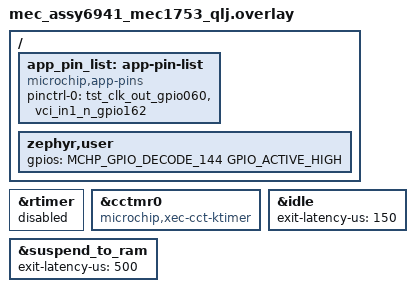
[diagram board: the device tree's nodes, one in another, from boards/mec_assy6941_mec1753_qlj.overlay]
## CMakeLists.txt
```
# Copyright (c) 2026 Microchip Technology Inc.
#
# SPDX-License-Identifier: Apache-2.0

cmake_minimum_required(VERSION 3.20.0)

find_package(Zephyr REQUIRED HINTS $ENV{ZEPHYR_BASE})
project(xec_cct_kt)

target_sources(app PRIVATE src/main.c src/xec_vci.c)
```

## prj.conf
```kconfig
# Copyright (c) 2026 Microchip Technology Inc.
# SPDX-License-Identifier: Apache-2.0

# Tickless kernel and PM are prerequisites for the system-timer LPM companion;
# MCHP_XEC_CCT_KTIMER then selects SYSTEM_TIMER_LPM_COMPANION_HOOKS.
CONFIG_TICKLESS_KERNEL=y
CONFIG_PM=y

CONFIG_STDOUT_CONSOLE=y

# main.c applies the test-clock-out pin state via the pinctrl API.
CONFIG_PINCTRL=y

CONFIG_SOC_MEC_PM_DBG_PCR_CLK_REQ_VBM=y
```

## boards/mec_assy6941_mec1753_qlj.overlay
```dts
/*
 * Copyright (c) 2026 Microchip Technology Inc.
 *
 * SPDX-License-Identifier: Apache-2.0
 *
 * Make the MEC1753-QLJ board use the capture-compare timer (CCT) as the Zephyr
 * kernel timer instead of the default RTOS timer.
 *
 * - cctmr0 is bound to the CCT kernel-timer driver and given the values its
 *   binding/driver require (compatible, the Compare0/Compare1 interrupts and
 *   GIRQ encodings, PCR sleep-enable, and input clock).
 * - The RTOS timer remains as the low-power companion. In HOOKS mode no driver
 *   binds it; the CCT driver reaches it by the &rtimer node label, so the node
 *   stays present but disabled (which also keeps MCHP_XEC_RTOS_TIMER from being
 *   auto-selected and conflicting with the CCT kernel timer).
 */

#include <zephyr/dt-bindings/gpio/microchip-xec-gpio.h>
#include <zephyr/dt-bindings/interrupt-controller/mchp-xec-ecia.h>
#include <zephyr/dt-bindings/clock/mchp_xec_pcr.h>

/ {
	/*
	 * Route the MEC internal test clock to GPIO060 (alternate function 2) so
	 * the timer clock can be observed on a scope. This pin is not owned by any
	 * device driver, so main.c applies this state via the pinctrl API. NOTE:
	 * the pin mux only connects the pad; which clock is driven out is selected
	 * separately in SoC clock-out/VBAT test logic and is not configured here.
	 */
	app_pin_list: app-pin-list {
		/* App-local binding (dts/bindings/microchip,xec-test-clk-out.yaml)
		 * includes pinctrl-device.yaml so pinctrl-0/pinctrl-names are typed
		 * properties -- required for PINCTRL_DT_DEFINE() in main.c to compile.
		 */
		compatible = "microchip,app-pins";
		pinctrl-0 = <&tst_clk_out_gpio060 &vci_in1_n_gpio162>;
		pinctrl-names = "default";
	};

	zephyr,user {
		gpios = <MCHP_GPIO_DECODE_144 GPIO_ACTIVE_HIGH>;
	};
};

&rtimer {
	status = "disabled";
};

&cctmr0 {
	compatible = "microchip,xec-cct-ktimer";
	status = "okay";
};

/*
 * The PM core arms the LPM companion (z_sys_clock_lpm_enter) only when the
 * chosen power state has a non-zero exit-latency-us: the single
 * sys_clock_set_timeout(..., idle=true) call at subsys/pm/pm.c is gated on
 * exit_latency_ticks > 0. Without it, SUSPEND_TO_RAM powers the PLL (and the
 * CCT) off with no companion armed and therefore no wake source, so the core
 * hangs in __WFI(). The board's power-states omit exit-latency-us, so add it
 * here. Values must be >= one tick (100 us at 10 kHz) to survive the floor
 * conversion; these are placeholders pending measured PLL-relock/restore time.
 */
&idle {
	exit-latency-us = <150>;
};

&suspend_to_ram {
	exit-latency-us = <500>;
};
```

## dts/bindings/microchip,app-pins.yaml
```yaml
# Copyright (c) 2026 Microchip Technology Inc.
# SPDX-License-Identifier: Apache-2.0

description: |
  Sample-only pin-control holder for routing the MEC internal test clock to a
  GPIO pad (see samples/boards/microchip/xec_cct_kt). It has no registers and no
  driver; it exists solely so a pin-control state can be declared and applied
  from the application with the pinctrl API.

  Including pinctrl-device.yaml is what makes the pinctrl-0/pinctrl-names
  properties typed in the binding, which is required for PINCTRL_DT_DEFINE()
  (it expands to DT_FOREACH_PROP_ELEM(node, pinctrl_0, ...), whose helper macro
  is only generated for a binding-declared property).

compatible: "microchip,app-pins"

include: [base.yaml, pinctrl-device.yaml]
```

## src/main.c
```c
/*
 * Copyright (c) 2026 Microchip Technology Inc.
 *
 * SPDX-License-Identifier: Apache-2.0
 */

#include <soc.h>
#include <zephyr/kernel.h>
#include <zephyr/sys/printk.h>
#include <zephyr/drivers/gpio.h>
#include <zephyr/drivers/pinctrl.h>

#include "xec_vci.h"

/* #define USE_VCI_IN1_BUTTON */

#define SLEEP_MS   3000U
#define ITERATIONS 0

#define XEC_VBAT_MEM_BASE  DT_REG_ADDR(DT_NODELABEL(bbram))
#define XEC_ECS_BASE       DT_REG_ADDR(DT_NODELABEL(ecs))
#define XEC_ECS_DBG_CR_OFS 0x20U

/* Test-clock-out pad (GPIO060, AF2). Not owned by a device driver, so define
 * its pin-control config here and apply it manually from main().
 */
#define APP_PINS_NODE DT_NODELABEL(app_pin_list)
PINCTRL_DT_DEFINE(APP_PINS_NODE);
static const struct pinctrl_dev_config *app_pins_pcfg = PINCTRL_DT_DEV_CONFIG_GET(APP_PINS_NODE);

#ifndef USE_VCI_IN1_BUTTON
#define ZEPHYR_USER_NODE DT_PATH(zephyr_user)
static const struct gpio_dt_spec sw2_spec = GPIO_DT_SPEC_GET(ZEPHYR_USER_NODE, gpios);
static volatile uint32_t sw2_falling_edge;
static struct gpio_callback sw2_cbs;
static void sw2_cb(const struct device *port, struct gpio_callback *cb, gpio_port_pins_t pins);
#endif

/*
 * Exercise the CCT kernel timer across tickless sleeps. Each iteration sleeps
 * long enough to let the PM policy enter a low-power state (the board's
 * suspend-to-ram residency is 2 s), which hands timekeeping to the 32 KHz RTOS
 * timer companion. If both the system timer and the LPM hooks are correct, the
 * uptime delta and the free-running cycle-counter delta should both track the
 * requested sleep time.
 */
int main(void)
{
	uint32_t i = 0, r = 0;
	int ret = 0;

	printk("XEC CCT kernel timer sample\n");
	printk("system timer HW cycles/sec: %u\n", sys_clock_hw_cycles_per_sec());
	printk("ticks/sec: %d\n", CONFIG_SYS_CLOCK_TICKS_PER_SEC);

	/* Route the test clock to GPIO060 for scope measurement. */
	ret = pinctrl_apply_state(app_pins_pcfg, PINCTRL_STATE_DEFAULT);
	if (ret != 0) {
		printk("app-pin-list pinctrl apply failed: %d\n", ret);
	} else {
		printk("test clock routed to GPIO060 (AF2)\n");
		printk("VCI_IN1 pin function enabled\n");
	}

#ifdef USE_VCI_IN1_BUTTON
	printk("Using VCI_IN1 on switch S4 of EVB as trigger");
	mchp_vci_in_input_enable(BIT(MEC_VCI_IN1_POS));
	mchp_vci_in_latch_enable(BIT(MEC_VCI_IN1_POS));
	mchp_vci_edge_detect_clr_all();
	mchp_vci_in_latch_reset(BIT(MEC_VCI_IN1_POS));
#else
	printk("Using GPIO144 connected to switch SW2 of MECC as trigger\n");
	gpio_flags_t sw2_flags = GPIO_INPUT | GPIO_INT_EDGE_FALLING;
	gpio_port_pins_t pin_mask = BIT(sw2_spec.pin);

	ret = gpio_pin_configure_dt(&sw2_spec, sw2_flags);
	if (ret != 0) {
		printk("configuration of SW2 GPIO as input failed (%d)\n", ret);
		return ret;
	}

	gpio_init_callback(&sw2_cbs, sw2_cb, pin_mask);
	gpio_add_callback(sw2_spec.port, &sw2_cbs);

	ret = gpio_pin_interrupt_configure_dt(&sw2_spec, sw2_flags);
	if (ret != 0) {
		printk("configure SW2 GPIO falling edge interrupt failed (%d)\n", ret);
		return ret;
	}
#endif

#ifdef USE_VCI_IN1_BUTTON
	printk("Disconnect Debugger and press switch S4 when ready\n");
#else
	printk("Disconnect Debugger and press switch SW2 when ready\n");
#endif

#ifdef USE_VCI_IN1_BUTTON
	r = mchp_vci_pedge_detect() & mchp_vci_nedge_detect();
	while ((r & BIT(MEC_VCI_IN1_POS)) == 0) {
		r = mchp_vci_pedge_detect() & mchp_vci_nedge_detect();
	}
	printk("Button S4 pressed. Disabling Debug interface\n");
#else
	sw2_falling_edge = 0;
	while (sw2_falling_edge == 0) {
	}
	printk("Button SW2 pressed. Disabling Debug interface\n");
#endif

	sys_write32(0, XEC_ECS_BASE + XEC_ECS_DBG_CR_OFS);
	sys_write32(0, 0xE000EDFCU);
	sys_write32(0xA05F0000U, 0xE0000EDFU);
	sys_write32(0xC5ACCE55U, 0xE0000FB0U);
	sys_write32(0, 0xE0000FB0U);
	sys_write32(0, 0xE0000E80U);
	sys_write32(0, 0xE0040304U);
	sys_write32(0, 0xE000EDFCU);

	r = sys_read32(XEC_ECS_BASE + XEC_ECS_DBG_CR_OFS);
	printk("ECS reg 0x%08x = 0x%08x\n", (XEC_ECS_BASE + XEC_ECS_DBG_CR_OFS), r);

#if ITERATIONS == 0
	while (true) {
		i++;
#else
	for (i = 0; i < ITERATIONS; i++) {
#endif
		uint32_t cyc0 = k_cycle_get_32();
		int64_t up0 = k_uptime_get();

		k_msleep(SLEEP_MS);

		uint32_t cyc1 = k_cycle_get_32();
		int64_t up1 = k_uptime_get();

		/* Unsigned subtraction is wrap-correct for the 32-bit counter. */
		uint32_t dcyc = cyc1 - cyc0;

		printk("iter %u: requested %u ms, uptime +%lld ms, "
		       "cycles +%u (%u ms by cycle count)\n",
		       i, SLEEP_MS, (long long)(up1 - up0), dcyc, k_cyc_to_ms_near32(dcyc));

		r = sys_read32(XEC_VBAT_MEM_BASE);
		printk("PCR CLK_REQ0 = 0x%08x\n", r);
		r = sys_read32(XEC_VBAT_MEM_BASE + 4U);
		printk("PCR CLK_REQ1 = 0x%08x\n", r);
		r = sys_read32(XEC_VBAT_MEM_BASE + 8U);
		printk("PCR CLK_REQ2 = 0x%08x\n", r);
		r = sys_read32(XEC_VBAT_MEM_BASE + 0xCU);
		printk("PCR CLK_REQ3 = 0x%08x\n", r);
		r = sys_read32(XEC_VBAT_MEM_BASE + 0x10U);
		printk("PCR CLK_REQ4 = 0x%08x\n", r);

		k_busy_wait(1000U); /* Let UART TX FIFO drain */
	}

	printk("Sample complete\n");

	return 0;
}

#ifndef USE_VCI_IN1_BUTTON
static void sw2_cb(const struct device *port, struct gpio_callback *cb, gpio_port_pins_t pins)
{
	sw2_falling_edge = 1U;
}
#endif
```

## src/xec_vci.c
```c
/*
 * Copyright 2024 Microchip Technology Inc. and its subsidiaries.
 *
 * SPDX-License-Identifier: Apache-2.0
 */
#include <stddef.h>
#include <stdint.h>
#include <soc.h>
#include <zephyr/kernel.h>
#include <zephyr/sys/printk.h>
#include <zephyr/drivers/pinctrl.h>

#include "xec_vci.h"

#define XEC_VCI_NODE DT_NODELABEL(vci0)

#define XEC_VCI_REG_BASE (mm_reg_t)(DT_REG_ADDR(XEC_VCI_NODE))

#define XEC_VCI_CR_OFS            0
#define XEC_VCI_LATCH_EN_OFS      4U
#define XEC_VCI_LATCH_RST_OFS     8U
#define XEC_VCI_INPUT_EN_OFS      0xCU
#define XEC_VCI_HOLD_OFF_CNT_OFS  0x10U
#define XEC_VCI_IN_POLARITY_OFS   0x14U
#define XEC_VCI_IN_POSEDG_STS_OFS 0x18U
#define XEC_VCI_IN_NEGEDG_STS_OFS 0x1CU
#define XEC_VCI_IN_VBAT_BUFEN_OFS 0x20U

/* Control register */
#define XEC_VCI_CR_LIN_POS          0 /* R/O latched input states */
#define XEC_VCI_CR_LIN_MSK          GENMASK(6, 0)
#define XEC_VCI_CR_LIN_GET(r)       FIELD_GET(XEC_VCI_CR_LIN_MSK, (r))
#define XEC_VCI_CR_OVRD_IN_POS      8  /* R/O current VCI_OVRD_IN pin state*/
#define XEC_VCI_CR_OUTV_POS         9  /* R/O current VCI_OUT pin state */
#define XEC_VCI_CR_FW_OUTV_POS      10 /* R/W VCI_OUT pin state under FW control */
#define XEC_VCI_CR_FW_EN_POS        11 /* R/W enable FW control of VCI_OUT pin state */
#define XEC_VCI_CR_FILT_BYPASS_POS  12 /* R/W bypass(disable) input filters */
#define XEC_VCI_CR_WK_ALRM_STS_POS  16 /* R/O Week alarm asserted WEEK_ALRM_LS signal */
#define XEC_VCI_CR_RTC_ALRM_STS_POS 17 /* R/O RTC asserted its alarm signal */
#define XEC_VCI_CR_SEL_SYSPP_POS    18 /* R/W 1=VCI_IN3 becomes SYSPWR_PRES */

#define XEC_VCI_CR_ALL_IN_STATE_MSK                                                                \
	(XEC_VCI_CR_LIN_MSK | BIT(XEC_VCI_CR_OVRD_IN_POS) | BIT(XEC_VCI_CR_OUTV_POS) |             \
	 BIT(XEC_VCI_CR_WK_ALRM_STS_POS) | BIT(XEC_VCI_CR_RTC_ALRM_STS_POS))

/* Latch enable and Latch reset registers */
#define XEC_VCI_LER_IN_POS       0 /* Latch enable/reset for VCI_IN pins */
#define XEC_VCI_LER_IN_MSK       GENMASK(6, 0)
#define XEC_VCI_LER_SET(v)       FIELD_PREP(XEC_VCI_LER_IN_MSK, (v))
#define XEC_VCI_LER_GET(r)       FIELD_GET(XEC_VCI_LER_IN_MSK, (r))
#define XEC_VCI_LER_WK_ALRM_POS  16
#define XEC_VCI_LER_RTC_ALRM_POS 17

#define XEC_VCI_LER_ALL_MSK                                                                        \
	(XEC_VCI_LER_IN_MSK | BIT(XEC_VCI_LER_WK_ALRM_POS) | BIT(XEC_VCI_LER_RTC_ALRM_POS))

/* Input enable register */
#define XEC_VCI_INPUT_EN_VIN_POS    0
#define XEC_VCI_INPUT_EN_VIN_MSK    GENMASK(6, 0)
#define XEC_VCI_INPUT_EN_VIN_SET(v) FIELD_PREP(XEC_VCI_INPUT_EN_VIN_MSK, (v))
#define XEC_VCI_INPUT_EN_VIN_GET(r) FIELD_GET(XEC_VCI_INPUT_EN_VIN_MSK, (r))

/* Hold off count register. Units of 125 ms */
#define XEC_VCI_HOLD_OFF_CNT_TM_POS    0
#define XEC_VCI_HOLD_OFF_CNT_TM_MSK    GENMASK(7, 0)
#define XEC_VCI_HOLD_OFF_CNT_TM_SET(v) FIELD_PREP(XEC_VCI_HOLD_OFF_CNT_TM_MSK, (v))
#define XEC_VCI_HOLD_OFF_CNT_TM_GET(r) FIELD_GET(XEC_VCI_HOLD_OFF_CNT_TM_MSK, (r))

/* Input Polarity register */
#define XEC_VCI_IN_POLARITY_POS    0
#define XEC_VCI_IN_POLARITY_MSK    GENMASK(6, 0)
#define XEC_VCI_IN_POLARITY_SET(v) FIELD_PREP(XEC_VCI_IN_POLARITY_MSK, (v))
#define XEC_VCI_IN_POLARITY_GET(r) FIELD_GET(XEC_VCI_IN_POLARITY_MSK, (r))

/* Positive and Negative Edge detect registers */
#define XEC_VCI_EDG_DET_POS    0
#define XEC_VCI_EDG_DET_MSK    GENMASK(6, 0)
#define XEC_VCI_EDG_DET_SET(v) FIELD_PREP(XEC_VCI_EDG_DET_MSK, (v))
#define XEC_VCI_EDG_DET_GET(r) FIELD_GET(XEC_VCI_EDG_DET_MSK, (r))

/* Input VBAT buffer enable register */
#define XEC_VCI_IN_VB_EN_POS    0
#define XEC_VCI_IN_VB_EN_MSK    GENMASK(6, 0)
#define XEC_VCI_IN_VB_EN_SET(v) FIELD_PREP(XEC_VCI_IN_VB_EN_MSK, (v))
#define XEC_VCI_IN_VB_EN_GET(r) FIELD_GET(XEC_VCI_IN_VB_EN_MSK, (r))

/* VCI_IN[0:6] are always bits[0:5] in registers referencing them */
#define XEC_VCI_IN_0_6_MASK 0x3fu

/* -------- VBAT Powered Control Interface (VCI) API -------- */

int mchp_xec_vci_pin_disable(uint8_t vci_id)
{
	mm_reg_t base = XEC_VCI_REG_BASE;

	if (vci_id >= MCHP_XEC_VCI_IN_ID_MAX) {
		return -EINVAL;
	}

	sys_clear_bit(base + XEC_VCI_INPUT_EN_OFS, vci_id);
	sys_clear_bit(base + XEC_VCI_IN_VBAT_BUFEN_OFS, vci_id);

	return 0;
}

/* VCI_IN pins filter enable/disable */
void mchp_vci_in_filter_enable(uint8_t enable)
{
	mm_reg_t base = XEC_VCI_REG_BASE;

	if (enable != 0) {
		sys_clear_bit(base + XEC_VCI_CR_OFS, XEC_VCI_CR_FILT_BYPASS_POS);
	} else {
		sys_set_bit(base + XEC_VCI_CR_OFS, XEC_VCI_CR_FILT_BYPASS_POS);
	}
}

/* Return current state of VCI pin inputs. If latching is enabled
 * the current state is the latched state otherwise the state is
 * live pin after filtering and polarity are applied.
 * b[6:0] = VCI_IN[6:0]
 * b[8] = current VCI_OVRD_IN state
 * b[9] = current VCI_OUT state
 * b[16] = Week Alarm state
 * b[17] = RTC Alaram state
 */
uint32_t mchp_vci_in_pin_states(void)
{
	mm_reg_t base = XEC_VCI_REG_BASE;

	return sys_read32(base + XEC_VCI_CR_OFS) & XEC_VCI_CR_ALL_IN_STATE_MSK;
}

uint8_t mchp_vci_out_get(void)
{
	mm_reg_t base = XEC_VCI_REG_BASE;

	if ((sys_test_bit(base + XEC_VCI_CR_OFS, XEC_VCI_CR_OUTV_POS)) != 0) {
		return 1U;
	}

	return 0;
}

uint8_t mchp_vci_ovrd_in_get(void)
{
	mm_reg_t base = XEC_VCI_REG_BASE;

	if ((sys_test_bit(base + XEC_VCI_CR_OFS, XEC_VCI_CR_OVRD_IN_POS)) != 0) {
		return 1U;
	}

	return 0;
}

/* Enable software control of VCI_OUT pin state */
void mchp_vci_sw_vci_out_enable(uint8_t enable)
{
	mm_reg_t base = XEC_VCI_REG_BASE;

	if (enable != 0) {
		sys_set_bit(base + XEC_VCI_CR_OFS, XEC_VCI_CR_FW_EN_POS);
	} else {
		sys_clear_bit(base + XEC_VCI_CR_OFS, XEC_VCI_CR_FW_EN_POS);
	}
}

/* set the state of software controlled VCI_OUT pin state
 * This value has no effect on VCI_OUT pin unless the FW_EXT bit is 1.
 */
void mchp_vci_sw_vci_out_set(uint8_t pin_state)
{
	mm_reg_t base = XEC_VCI_REG_BASE;

	if (pin_state != 0) {
		sys_set_bit(base + XEC_VCI_CR_OFS, XEC_VCI_CR_FW_OUTV_POS);
	} else {
		sys_clear_bit(base + XEC_VCI_CR_OFS, XEC_VCI_CR_FW_OUTV_POS);
	}
}

uint32_t mchp_vci_in_latched_get(void)
{
	mm_reg_t base = XEC_VCI_REG_BASE;
	uint32_t r = sys_read32(base + XEC_VCI_CR_OFS);

	return XEC_VCI_CR_LIN_GET(r);
}

void mchp_vci_in_latch_enable(uint32_t latch_bitmap)
{
	mm_reg_t base = XEC_VCI_REG_BASE;
	uint32_t v = XEC_VCI_LER_SET(latch_bitmap);

	sys_set_bits(base + XEC_VCI_LATCH_EN_OFS, v);
}

void mchp_vci_in_latch_disable(uint32_t latch_bitmap)
{
	mm_reg_t base = XEC_VCI_REG_BASE;
	uint32_t v = XEC_VCI_LER_SET(latch_bitmap);

	sys_clear_bits(base + XEC_VCI_LATCH_EN_OFS, v);
}

uint32_t mchp_vci_in_latch_enable_get(void)
{
	mm_reg_t base = XEC_VCI_REG_BASE;
	uint32_t r = sys_read32(base + XEC_VCI_LATCH_EN_OFS);

	return XEC_VCI_LER_GET(r);
}

void mchp_vci_in_latch_reset(uint32_t latch_bitmap)
{
	mm_reg_t base = XEC_VCI_REG_BASE;

	sys_write32(latch_bitmap & XEC_VCI_LER_ALL_MSK, base + XEC_VCI_LATCH_RST_OFS);
}

void mchp_vci_in_input_enable(uint32_t latch_bitmap)
{
	mm_reg_t base = XEC_VCI_REG_BASE;

	sys_write32(XEC_VCI_INPUT_EN_VIN_SET(latch_bitmap), base + XEC_VCI_INPUT_EN_OFS);
	sys_write32(XEC_VCI_LER_SET(latch_bitmap), base + XEC_VCI_LATCH_RST_OFS);
}

uint32_t mchp_vci_in_input_enable_get(void)
{
	mm_reg_t base = XEC_VCI_REG_BASE;
	uint32_t r = sys_read32(base + XEC_VCI_INPUT_EN_OFS);

	return XEC_VCI_INPUT_EN_VIN_GET(r);
}

int mchp_vci_out_power_on_delay(uint32_t delay_ms)
{
	mm_reg_t base = XEC_VCI_REG_BASE;
	uint32_t delay_cnt = 0, v = 0;

	if (delay_ms == 0) { /* disable */
		v = 0;
	} else if ((delay_ms >= 125u) || (delay_ms <= (32u * 1000u))) {
		delay_cnt = delay_ms / 125u;
		if (((delay_cnt % 125u) > 62u) && (delay_cnt < 0xffu)) {
			delay_cnt++;
		}
	} else {
		return -ERANGE;
	}

	v = XEC_VCI_HOLD_OFF_CNT_TM_SET(v);
	soc_mmcr_mask_set(base + XEC_VCI_HOLD_OFF_CNT_OFS, v, XEC_VCI_HOLD_OFF_CNT_TM_MSK);

	return 0;
}

/* Set the polarity of selected VCI_IN[n] pins.
 * Polarity = 1 Active High
 *          = 0 Active Low
 */
void mchp_vci_in_polarity(uint32_t vci_in_bitmap, uint32_t polarity_bitmap)
{
	mm_reg_t base = XEC_VCI_REG_BASE;
	uint32_t v = sys_read32(base + XEC_VCI_IN_POLARITY_OFS);

	v &= (uint32_t)~(vci_in_bitmap);
	v |= (polarity_bitmap & vci_in_bitmap);
	sys_write32(v, base + XEC_VCI_IN_POLARITY_OFS);
}

uint32_t mchp_vci_pedge_detect(void)
{
	mm_reg_t base = XEC_VCI_REG_BASE;

	return XEC_VCI_EDG_DET_GET(sys_read32(base + XEC_VCI_IN_POSEDG_STS_OFS));
}

uint32_t mchp_vci_nedge_detect(void)
{
	mm_reg_t base = XEC_VCI_REG_BASE;

	return XEC_VCI_EDG_DET_GET(sys_read32(base + XEC_VCI_IN_NEGEDG_STS_OFS));
}

void mchp_vci_pedge_detect_clr(uint32_t bitmap)
{
	mm_reg_t base = XEC_VCI_REG_BASE;
	uint32_t v = XEC_VCI_EDG_DET_SET(bitmap);

	sys_write32(v, base + XEC_VCI_IN_POSEDG_STS_OFS);
}

void mchp_vci_nedge_detect_clr(uint32_t bitmap)
{
	mm_reg_t base = XEC_VCI_REG_BASE;
	uint32_t v = XEC_VCI_EDG_DET_SET(bitmap);

	sys_write32(v, base + XEC_VCI_IN_NEGEDG_STS_OFS);
}

void mchp_vci_edge_detect_clr_all(void)
{
	mm_reg_t base = XEC_VCI_REG_BASE;

	sys_write32(XEC_VCI_EDG_DET_MSK, base + XEC_VCI_IN_POSEDG_STS_OFS);
	sys_write32(XEC_VCI_EDG_DET_MSK, base + XEC_VCI_IN_NEGEDG_STS_OFS);
}

/* Select which VCI_IN[] pin edge detectors are enabled when the chip
 * is powered only by the VBAT power rail (VTR Core is off).
 * When the chip is on (VTR Core ON) this register has no effect on
 * the edge detector enables.
 */
uint32_t mchp_vci_vbat_edge_detect_get(void)
{
	mm_reg_t base = XEC_VCI_REG_BASE;
	uint32_t r = sys_read32(base + XEC_VCI_IN_VBAT_BUFEN_OFS);

	return XEC_VCI_IN_VB_EN_GET(r);
}

void mchp_vci_vbat_edge_detect_enable(uint32_t en_bitmap, uint32_t en_mask)
{
	mm_reg_t base = XEC_VCI_REG_BASE;
	uint32_t en = XEC_VCI_IN_VB_EN_SET(en_bitmap);
	uint32_t msk = XEC_VCI_IN_VB_EN_SET(en_mask);

	soc_mmcr_mask_set(base + XEC_VCI_IN_VBAT_BUFEN_OFS, en, msk);
}

/* end xec_vci.c */
```

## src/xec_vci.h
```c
/*
 * Copyright 2024 Microchip Technology Inc. and its subsidiaries.
 *
 * SPDX-License-Identifier: Apache-2.0
 */
#ifndef _XEC_VCI_H
#define _XEC_VCI_H

#include <stdbool.h>
#include <stddef.h>
#include <stdint.h>

/* Interfaces to any C modules */
#ifdef __cplusplus
extern "C" {
#endif

#define MCHP_XEC_VCI_IN0_ID    0
#define MCHP_XEC_VCI_IN1_ID    1U
#define MCHP_XEC_VCI_IN2_ID    2U
#define MCHP_XEC_VCI_IN3_ID    3U
#define MCHP_XEC_VCI_IN4_ID    4U
#define MCHP_XEC_VCI_IN5_ID    5U
#define MCHP_XEC_VCI_IN_ID_MAX 6U

enum mec_vci_sel {
	MEC_VCI_IN0_POS = 0,
	MEC_VCI_IN1_POS,
	MEC_VCI_IN2_POS,
	MEC_VCI_IN3_POS,
	MEC_VCI_IN4_POS,
	MEC_VCI_IN5_POS,
	MEC_VCI_IN6_POS,
	MEC_VCI_OVRD_IN_POS = 8,
	MEC_VCI_OUT_POS,
	MEC_VCI_IN_WEEK_ALARM_POS = 16,
	MEC_VCI_IN_RTC_ALARM_POS,
};

int mchp_xec_vci_pin_disable(uint8_t vci_id);

/* Return current state of VCI pin inputs. If latching is enabled
 * the current state is the latched state otherwise the state is
 * live pin after filtering and polarity are applied.
 * b[6:0] = VCI_IN[6:0]
 * b[8] = current VCI_OVRD_IN state
 * b[9] = current VCI_OUT state
 * b[16] = Week Alarm state
 * b[17] = RTC Alaram state
 */
uint32_t mchp_vci_in_pin_states(void);

/* VCI_IN pins filter enable/disable */
void mchp_vci_in_filter_enable(uint8_t enable);

uint8_t mchp_vci_out_get(void);
uint8_t mchp_vci_ovrd_in_get(void);

/* Enable software control of VCI_OUT pin state */
void mchp_vci_sw_vci_out_enable(uint8_t enable);

/* set the state of software controlled VCI_OUT pin state
 * This value has no effect on VCI_OUT pin unless the FW_EXT bit is 1.
 */
void mchp_vci_sw_vci_out_set(uint8_t pin_state);

/* Return bitmap of VCI_IN[6:0] input latched state */
uint32_t mchp_vci_in_latched_get(void);
void mchp_vci_in_latch_enable(uint32_t latch_bitmap);
void mchp_vci_in_latch_disable(uint32_t latch_bitmap);
uint32_t mchp_vci_in_latch_enable_get(void);

/* clear latched state of selected VCI inputs */
void mchp_vci_in_latch_reset(uint32_t latch_bitmap);

/* Set/get VCI_IN[] input enables */
void mchp_vci_in_input_enable(uint32_t latch_bitmap);
uint32_t mchp_vci_in_input_enable_get(void);

/* Program the delay after nSYS_SHDN asserts before VCI logic re-asserts
 * VCI_OUT. A value of zero disables the delay. Non-zero values should
 * be in the range [125, 32000] milliseconds.
 */
int mchp_vci_out_power_on_delay(uint32_t delay_ms);

/* Set the polarity of selected VCI_IN[n] pins.
 * Polarity = 1 Active High
 *          = 0 Active Low
 */
void mchp_vci_in_polarity(uint32_t vci_in_bitmap, uint32_t polarity_bitmap);

/* Return bitmap of detected positive edges on VCI_IN[] pins */
uint32_t mchp_vci_pedge_detect(void);

/* Return bitmap of detected negative edges on VCI_IN[] pins */
uint32_t mchp_vci_nedge_detect(void);

/* Clear edge detection logic */
void mchp_vci_pedge_detect_clr(uint32_t bitmap);
void mchp_vci_nedge_detect_clr(uint32_t bitmap);
void mchp_vci_edge_detect_clr_all(void);

/* Select which VCI_IN[] pin edge detector are enabled when the chip
 * is powered only by the VBAT power rail (VTR Core is off).
 * When the chip is on (VTR Core ON) this register has no effect on
 * the edge detector enables.
 */
uint32_t mchp_vci_vbat_edge_detect_get(void);
void mchp_vci_vbat_edge_detect_enable(uint32_t en_bitmap, uint32_t en_mask);

#ifdef __cplusplus
}
#endif

#endif /* #ifndef _XEC_VCI_H */
```
